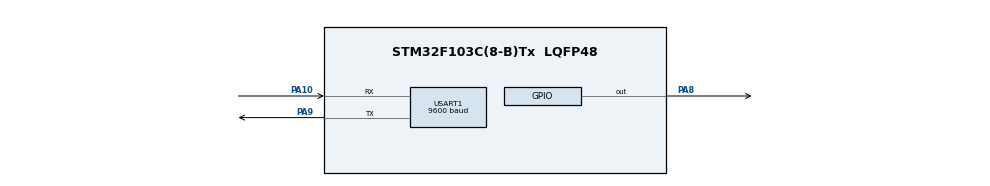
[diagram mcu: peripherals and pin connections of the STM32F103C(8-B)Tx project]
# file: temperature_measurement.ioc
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Mcu.Family=STM32F1
Mcu.Name=STM32F103C(8-B)Tx
Mcu.Package=LQFP48
NVIC.PriorityGroup=NVIC_PRIORITYGROUP_4
PA10.Mode=Asynchronous
PA10.Signal=USART1_RX
PA13.Mode=Serial_Wire
PA13.Signal=SYS_JTMS-SWDIO
PA14.Mode=Serial_Wire
PA14.Signal=SYS_JTCK-SWCLK
PA8.GPIO_Speed=GPIO_SPEED_FREQ_HIGH
PA8.PinState=GPIO_PIN_RESET
PA8.Signal=GPIO_Output
PA9.Mode=Asynchronous
PA9.Signal=USART1_TX
ProjectManager.HeapSize=0x200
ProjectManager.StackSize=0x400
ProjectManager.TargetToolchain=STM32CubeIDE
RCC.APB1Freq_Value=8000000
RCC.APB2Freq_Value=8000000
USART1.BaudRate=9600
USART1.VirtualMode=VM_ASYNC
board=custom

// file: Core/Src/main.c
/* USER CODE BEGIN Header */
/**
  ******************************************************************************
  * @file           : main.c
  * @brief          : Main program body
  ******************************************************************************
  * @attention
  *
  * Copyright (c) 2022 STMicroelectronics.
  * All rights reserved.
  *
  * This software is licensed under terms that can be found in the LICENSE file
  * in the root directory of this software component.
  * If no LICENSE file comes with this software, it is provided AS-IS.
  *
  ******************************************************************************
  */
/* USER CODE END Header */
#include "main.h"

/* USER CODE BEGIN Includes */
#include <stdio.h>
#include <string.h>
#include "temperature.h"
#include "systime.h"
/* USER CODE END Includes */

/* USER CODE BEGIN PD */
#define SAVING_DATA_ADDRESS 0x800FC00U   // Start address for saving maximum, middle and minimum temperature values.
#define SAVING_DATA_PERIOD 1799999       // Period for saving temperature values to the persistence storage (Internal Flash). It`s 30 minutes in microseconds.
#define MEASUREMENT_SMALL_PERIOD 14999   // Period for temperature measurement, if current temperature below 10°C. It`s 15 seconds in microseconds.
#define MEASUREMENT_NORMAL_PERIOD 59999  // Period for temperature measurement, if current temperature above 15°C. It`s 1 minute in microseconds.
#define UART_MESSAGE_BUFFER_SIZE 40      // Size of char buffer for message, which is printed via UART.
/* USER CODE END PD */

UART_HandleTypeDef huart1;

void SystemClock_Config(void);
static void MX_GPIO_Init(void);
static void MX_USART1_UART_Init(void);
/* USER CODE BEGIN PFP */
__STATIC_FORCEINLINE void Print_Temperature(float temperature);
__STATIC_FORCEINLINE void Rewrite_Temperature_Data(float* p_saving_data);
/* USER CODE END PFP */

int main(void)
{

  /* MCU Configuration--------------------------------------------------------*/

  /* Reset of all peripherals, Initializes the Flash interface and the Systick. */
  HAL_Init();

  /* Configure the system clock */
  SystemClock_Config();

  /* Initialize all configured peripherals */
  MX_GPIO_Init();
  MX_USART1_UART_Init();
  /* USER CODE BEGIN 2 */
  uint32_t measurement_period = MEASUREMENT_NORMAL_PERIOD;                            // Current period of measurement temperature.
  uint32_t measurement_start_time = Sys_Time_Get_Time() - MEASUREMENT_NORMAL_PERIOD;  // Start time for counting duty cycle of measurement temperature.
  uint32_t saving_start_time = Sys_Time_Get_Time() - SAVING_DATA_PERIOD;              // Start time for counting duty cycle of saving temperature values into flash.
  float current_temperature;                                                          // Current temperature value.
  float saving_data[3];
  /* USER CODE END 2 */

  /* Infinite loop */
  /* USER CODE BEGIN WHILE */
  while (1)
  {
    if(Sys_Time_Its_Time(measurement_start_time, measurement_period))
    {
      Measure_Temperature();
      current_temperature = Get_Current_Temperature();
      if(current_temperature < 10.0F)
      {
        measurement_period = MEASUREMENT_SMALL_PERIOD;
      }
      else if(current_temperature > 15.0F)
      {
        measurement_period = MEASUREMENT_NORMAL_PERIOD;
      }
      Print_Temperature(current_temperature);
      measurement_start_time = Sys_Time_Get_Time();
    }
    if(Sys_Time_Its_Time(saving_start_time, SAVING_DATA_PERIOD))
    {
      Get_Max_Middle_Min_Temperature(&saving_data[0], &saving_data[1], &saving_data[2]);
      Rewrite_Temperature_Data(saving_data);
      saving_start_time = Sys_Time_Get_Time();
    }
    /* USER CODE END WHILE */

  }
}

void SystemClock_Config(void)
{
  RCC_OscInitTypeDef RCC_OscInitStruct = {0};
  RCC_ClkInitTypeDef RCC_ClkInitStruct = {0};

  /** Initializes the RCC Oscillators according to the specified parameters
  * in the RCC_OscInitTypeDef structure.
  */
  RCC_OscInitStruct.OscillatorType = RCC_OSCILLATORTYPE_HSI;
  RCC_OscInitStruct.HSIState = RCC_HSI_ON;
  RCC_OscInitStruct.HSICalibrationValue = RCC_HSICALIBRATION_DEFAULT;
  RCC_OscInitStruct.PLL.PLLState = RCC_PLL_NONE;
  if (HAL_RCC_OscConfig(&RCC_OscInitStruct) != HAL_OK)
  {
    Error_Handler();
  }

  /** Initializes the CPU, AHB and APB buses clocks
  */
  RCC_ClkInitStruct.ClockType = RCC_CLOCKTYPE_HCLK|RCC_CLOCKTYPE_SYSCLK
                              |RCC_CLOCKTYPE_PCLK1|RCC_CLOCKTYPE_PCLK2;
  RCC_ClkInitStruct.SYSCLKSource = RCC_SYSCLKSOURCE_HSI;
  RCC_ClkInitStruct.AHBCLKDivider = RCC_SYSCLK_DIV1;
  RCC_ClkInitStruct.APB1CLKDivider = RCC_HCLK_DIV1;
  RCC_ClkInitStruct.APB2CLKDivider = RCC_HCLK_DIV1;

  if (HAL_RCC_ClockConfig(&RCC_ClkInitStruct, FLASH_LATENCY_0) != HAL_OK)
  {
    Error_Handler();
  }
}

static void MX_USART1_UART_Init(void)
{

  huart1.Instance = USART1;
  huart1.Init.BaudRate = 9600;
  huart1.Init.WordLength = UART_WORDLENGTH_8B;
  huart1.Init.StopBits = UART_STOPBITS_1;
  huart1.Init.Parity = UART_PARITY_NONE;
  huart1.Init.Mode = UART_MODE_TX_RX;
  huart1.Init.HwFlowCtl = UART_HWCONTROL_NONE;
  huart1.Init.OverSampling = UART_OVERSAMPLING_16;
  if (HAL_UART_Init(&huart1) != HAL_OK)
  {
    Error_Handler();
  }

}

static void MX_GPIO_Init(void)
{
  GPIO_InitTypeDef GPIO_InitStruct = {0};

  /* GPIO Ports Clock Enable */
  __HAL_RCC_GPIOA_CLK_ENABLE();

  /*Configure GPIO pin Output Level */
  HAL_GPIO_WritePin(GPIOA, GPIO_PIN_8, GPIO_PIN_RESET);

  /*Configure GPIO pin : PA8 */
  GPIO_InitStruct.Pin = GPIO_PIN_8;
  GPIO_InitStruct.Mode = GPIO_MODE_OUTPUT_PP;
  GPIO_InitStruct.Pull = GPIO_NOPULL;
  GPIO_InitStruct.Speed = GPIO_SPEED_FREQ_HIGH;
  HAL_GPIO_Init(GPIOA, &GPIO_InitStruct);

}

/* USER CODE BEGIN 4 */
__STATIC_FORCEINLINE void Print_Temperature(float temperature)
{
  char uart_message[UART_MESSAGE_BUFFER_SIZE];
  sprintf(uart_message, "Current temperature: %.1f\r\n", temperature);
  HAL_UART_Transmit(&huart1, (uint8_t*)uart_message, (strlen(uart_message) * sizeof(char)), 1000);
}

__STATIC_FORCEINLINE void Rewrite_Temperature_Data(float* p_saving_data)
{
  static FLASH_EraseInitTypeDef erase_struct =
  {
    .TypeErase = FLASH_TYPEERASE_PAGES,
    .PageAddress = SAVING_DATA_ADDRESS,
    .NbPages = 1
  };
  uint32_t page_error;
  HAL_FLASH_Unlock();
  HAL_FLASHEx_Erase(&erase_struct, &page_error);
  for(uint8_t i = 0; i < 3; i++)
  {
    HAL_FLASH_Program(FLASH_TYPEPROGRAM_WORD, (SAVING_DATA_ADDRESS + (sizeof(float) * i)), p_saving_data[i]);
  }
  HAL_FLASH_Lock();
}
/* USER CODE END 4 */

void Error_Handler(void)
{
  __disable_irq();
  while (1)
  {
  }
}
